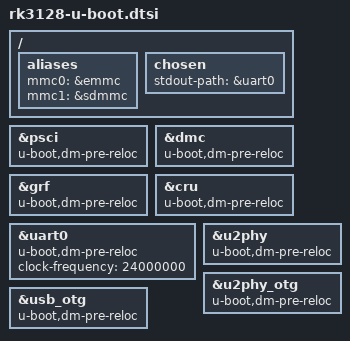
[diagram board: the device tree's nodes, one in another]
/*
 * (C) Copyright 2018 Rockchip Electronics Co., Ltd
 *
 * SPDX-License-Identifier:     GPL-2.0+
 */

/ {
	aliases {
		mmc0 = &emmc;
		mmc1 = &sdmmc;
	};

	chosen {
		stdout-path = &uart0;
	};
};

&psci {
	u-boot,dm-pre-reloc;
	status = "okay";
};

&dmc {
	u-boot,dm-pre-reloc;
};

&grf {
	u-boot,dm-pre-reloc;
};

&cru {
	u-boot,dm-pre-reloc;
};

&uart0 {
	u-boot,dm-pre-reloc;
	clock-frequency = <24000000>;
};

&u2phy {
	u-boot,dm-pre-reloc;
	status = "okay";
};

&u2phy_otg {
	u-boot,dm-pre-reloc;
	status = "okay";
};

&usb_otg {
	u-boot,dm-pre-reloc;
	status = "okay";
};
